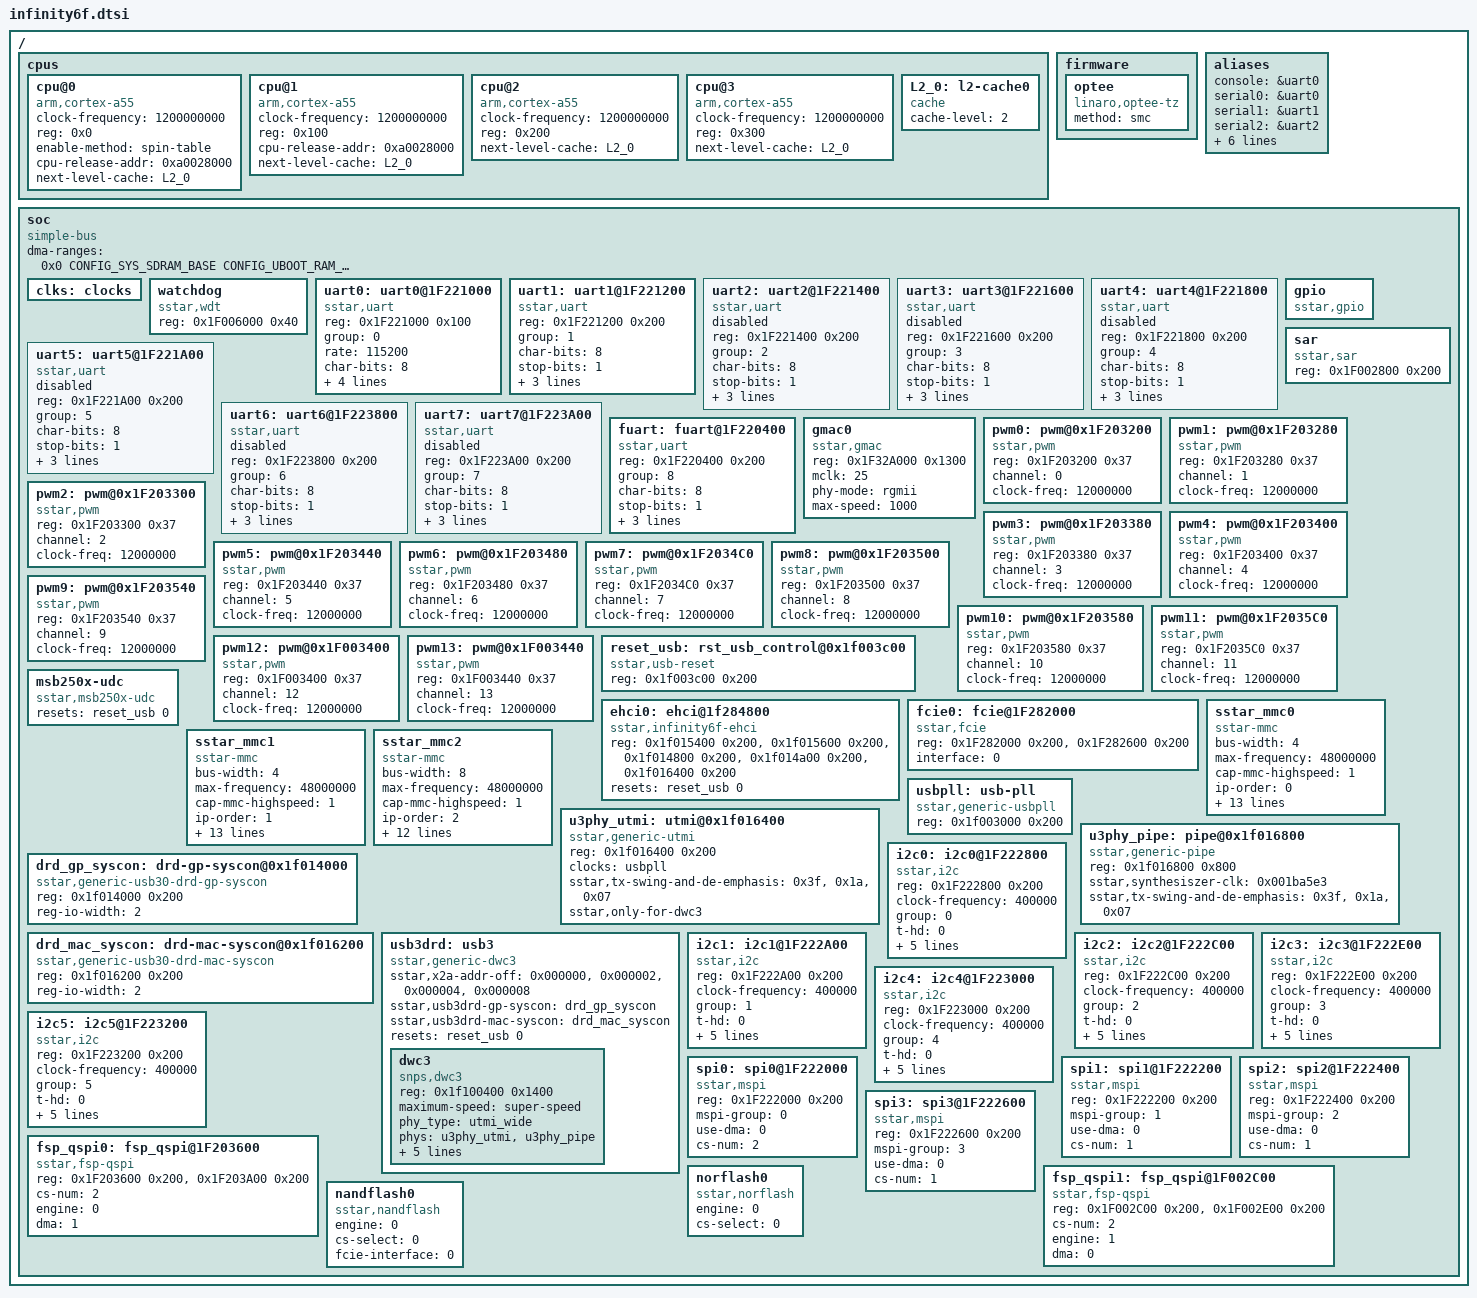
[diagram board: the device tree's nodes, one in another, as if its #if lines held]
/*
* infinity6f.dtsi- Sigmastar
*
* Copyright (c) [2019~2020] SigmaStar Technology.
*
*
* This software is licensed under the terms of the GNU General Public
* License version 2, as published by the Free Software Foundation, and
* may be copied, distributed, and modified under those terms.
*
* This program is distributed in the hope that it will be useful,
* but WITHOUT ANY WARRANTY; without even the implied warranty of
* MERCHANTABILITY or FITNESS FOR A PARTICULAR PURPOSE.  See the
* GNU General Public License version 2 for more details.
*
*/

#include <generated/autoconf.h>
#include "../../../include/configs/infinity6f.h"
#include "../../../drivers/sstar/include/infinity6f/gpio.h"

/*
 * Reserve for TF-A OPTEE and riu recorder
 * 0x24000000 - 0x2403FFFF : TF-A
 * 0x24100000 - 0x241FFFFF : riu recorder
 * 0x24200000 - 0x249FFFFF : OPTEE
 */
/memreserve/ 0x24000000 0x00A00000;

/ {
    cpus {
        #address-cells = <1>;
        #size-cells = <0>;

        cpu@0 {
            device_type = "cpu";
            compatible = "arm,cortex-a55";
            clock-frequency = <1200000000>;
            //clocks = <&CLK_cpupll_clk>;
            reg = <0x0>;
            enable-method = "spin-table";
            cpu-release-addr = <0xa0028000>;
            next-level-cache = <&L2_0>;
        };
#ifndef CONFIG_NO_SMP
        cpu@1 {
            device_type = "cpu";
            compatible = "arm,cortex-a55";
            clock-frequency = <1200000000>;
            reg = <0x100>;
            cpu-release-addr = <0xa0028000>;
            next-level-cache = <&L2_0>;
        };

        cpu@2 {
            device_type = "cpu";
            compatible = "arm,cortex-a55";
            clock-frequency = <1200000000>;
            reg = <0x200>;
            next-level-cache = <&L2_0>;
        };

        cpu@3 {
            device_type = "cpu";
            compatible = "arm,cortex-a55";
            clock-frequency = <1200000000>;
            reg = <0x300>;
            next-level-cache = <&L2_0>;
        };
#endif
        L2_0: l2-cache0 {
            compatible = "cache";
            cache-level = <2>;
        };
    };

#ifdef CONFIG_OPTEE
    firmware {
        optee {
            compatible = "linaro,optee-tz";
            method = "smc";
        };
    };
#endif

    aliases {
        console = &uart0;
        serial0 = &uart0;
        serial1 = &uart1;
        serial2 = &uart2;
        serial3 = &uart3;
        serial4 = &uart4;
        serial5 = &uart5;
        serial6 = &uart6;
        serial7 = &uart7;
        serial8 = &fuart;
    };

    soc {
        compatible = "simple-bus";
        #address-cells = <1>;
        #size-cells = <1>;
        dma-ranges = <0x0 CONFIG_SYS_SDRAM_BASE CONFIG_UBOOT_RAM_SIZE>;
        ranges;

        clks: clocks{
            #address-cells = <1>;
            #size-cells = <1>;
            ranges;
        };

        watchdog: watchdog {
            compatible = "sstar,wdt";
            reg = <0x1F006000 0x40>;
            status = "okay";
        };

        uart0: uart0@1F221000 {
            compatible = "sstar,uart";
            reg = <0x1F221000 0x100>;
            group = <0>;
            rate = <115200>;
            char-bits = <8>;
            stop-bits = <1>;
            parity-en = <0>;
            auto-flow = <0>;
            tolerance = <3>;
            status = "okay";
        };

        uart1: uart1@1F221200 {
            compatible = "sstar,uart";
            reg = <0x1F221200 0x200>;
            group = <1>;
            char-bits = <8>;
            stop-bits = <1>;
            parity-en = <0>; // 0-disable; 1-odd; 2-even.
            auto-flow = <0>;
            tolerance = <3>;
            status = "okay";
        };

        uart2: uart2@1F221400 {
            compatible = "sstar,uart";
            reg = <0x1F221400 0x200>;
            group = <2>;
            char-bits = <8>;
            stop-bits = <1>;
            parity-en = <0>; // 0-disable; 1-odd; 2-even.
            auto-flow = <0>;
            tolerance = <3>;
            status = "disabled";
        };

        uart3: uart3@1F221600 {
            compatible = "sstar,uart";
            reg = <0x1F221600 0x200>;
            group = <3>;
            char-bits = <8>;
            stop-bits = <1>;
            parity-en = <0>; // 0-disable; 1-odd; 2-even.
            auto-flow = <0>;
            tolerance = <3>;
            status = "disabled";
        };

        uart4: uart4@1F221800 {
            compatible = "sstar,uart";
            reg = <0x1F221800 0x200>;
            group = <4>;
            char-bits = <8>;
            stop-bits = <1>;
            parity-en = <0>; // 0-disable; 1-odd; 2-even.
            auto-flow = <0>;
            tolerance = <3>;
            status = "disabled";
        };

        uart5: uart5@1F221A00 {
            compatible = "sstar,uart";
            reg = <0x1F221A00 0x200>;
            group = <5>;
            char-bits = <8>;
            stop-bits = <1>;
            parity-en = <0>; // 0-disable; 1-odd; 2-even.
            auto-flow = <0>;
            tolerance = <3>;
            status = "disabled";
        };

        uart6: uart6@1F223800 {
            compatible = "sstar,uart";
            reg = <0x1F223800 0x200>;
            group = <6>;
            char-bits = <8>;
            stop-bits = <1>;
            parity-en = <0>; // 0-disable; 1-odd; 2-even.
            auto-flow = <0>;
            tolerance = <3>;
            status = "disabled";
        };

        uart7: uart7@1F223A00 {
            compatible = "sstar,uart";
            reg = <0x1F223A00 0x200>;
            group = <7>;
            char-bits = <8>;
            stop-bits = <1>;
            parity-en = <0>; // 0-disable; 1-odd; 2-even.
            auto-flow = <0>;
            tolerance = <3>;
            status = "disabled";
        };

        fuart: fuart@1F220400 {
            compatible = "sstar,uart";
            reg = <0x1F220400 0x200>;
            group = <8>;
            char-bits = <8>;
            stop-bits = <1>;
            parity-en = <0>; // 0-disable; 1-odd; 2-even.
            auto-flow = <0>;
            tolerance = <3>;
            status = "okay";
        };

        gmac0: gmac0 {
            compatible = "sstar,gmac", "snps,dwmac-5.10a";
            reg = <0x1F32A000 0x1300>;
            clock-names = "gmac-clk", "mclk";
            mclk = /bits/ 8 <25>; // Mclk frequency : 0, 25M, 50M
            phy-mode = "rgmii";
            max-speed = <1000>;
            status = "okay";
        };

        gpio: gpio {
            compatible = "sstar,gpio";
            status = "okay";
        };

        sar: sar {
            compatible = "sstar,sar";
            reg = <0x1F002800 0x200>;
            status = "okay";
        };

        pwm0: pwm@0x1F203200{
            compatible = "sstar,pwm";
            reg = <0x1F203200 0x37>;
            channel = <0>;
            clock-freq = <12000000>;
            status = "okay";
        };

        pwm1: pwm@0x1F203280 {
            compatible = "sstar,pwm";
            reg = <0x1F203280 0x37>;
            channel = <1>;
            clock-freq = <12000000>;
            status = "okay";
        };

        pwm2: pwm@0x1F203300 {
            compatible = "sstar,pwm";
            reg = <0x1F203300 0x37>;
            channel = <2>;
            clock-freq = <12000000>;
            status = "okay";
        };

        pwm3: pwm@0x1F203380 {
            compatible = "sstar,pwm";
            reg = <0x1F203380 0x37>;
            channel = <3>;
            clock-freq = <12000000>;
            status = "okay";
        };

        pwm4: pwm@0x1F203400 {
            compatible = "sstar,pwm";
            reg = <0x1F203400 0x37>;
            channel = <4>;
            clock-freq = <12000000>;
            status = "okay";
        };

        pwm5: pwm@0x1F203440 {
            compatible = "sstar,pwm";
            reg = <0x1F203440 0x37>;
            channel = <5>;
            clock-freq = <12000000>;
            status = "okay";
        };

        pwm6: pwm@0x1F203480 {
            compatible = "sstar,pwm";
            reg = <0x1F203480 0x37>;
            channel = <6>;
            clock-freq = <12000000>;
            status = "okay";
        };

        pwm7: pwm@0x1F2034C0 {
            compatible = "sstar,pwm";
            reg = <0x1F2034C0 0x37>;
            channel = <7>;
            clock-freq = <12000000>;
            status = "okay";
        };

        pwm8: pwm@0x1F203500 {
            compatible = "sstar,pwm";
            reg = <0x1F203500 0x37>;
            channel = <8>;
            clock-freq = <12000000>;
            status = "okay";
        };

        pwm9: pwm@0x1F203540 {
            compatible = "sstar,pwm";
            reg = <0x1F203540 0x37>;
            channel = <9>;
            clock-freq = <12000000>;
            status = "okay";
        };

        pwm10: pwm@0x1F203580 {
            compatible = "sstar,pwm";
            reg = <0x1F203580 0x37>;
            channel = <10>;
            clock-freq = <12000000>;
            status = "okay";
        };

        pwm11: pwm@0x1F2035C0 {
            compatible = "sstar,pwm";
            reg = <0x1F2035C0 0x37>;
            channel = <11>;
            clock-freq = <12000000>;
            status = "okay";
        };

        pwm12: pwm@0x1F003400 {
            compatible = "sstar,pwm";
            reg = <0x1F003400 0x37>;
            channel = <12>;
            clock-freq = <12000000>;
            status = "okay";
        };

        pwm13: pwm@0x1F003440 {
            compatible = "sstar,pwm";
            reg = <0x1F003440 0x37>;
            channel = <13>;
            clock-freq = <12000000>;
            status = "okay";
        };

        reset_usb: rst_usb_control@0x1f003c00 {
            compatible = "sstar,usb-reset";
            reg = <0x1f003c00 0x200>;
            #reset-cells = <1>;
            status = "okay";
        };

        msb250x-udc {
            compatible = "sstar,msb250x-udc";
            resets = <&reset_usb 0>;
            status = "okay";
        };

        ehci0: ehci@1f284800{
            compatible = "sstar,infinity6f-ehci";
            reg = <0x1f015400 0x200>,
                  <0x1f015600 0x200>,
                  <0x1f014800 0x200>,
                  <0x1f014a00 0x200>,
                  <0x1f016400 0x200>;
            resets = <&reset_usb 0>;
            status = "okay";
        };

        fcie0: fcie@1F282000 {
            compatible = "sstar,fcie";
            reg = <0x1F282000 0x200>, <0x1F282600 0x200>;
            interface = <0>;
            status = "okay";
        };

        sstar_mmc0: sstar_mmc0 {
            compatible = "sstar-mmc";

            bus-width = <4>;
            max-frequency = <48000000>;
            cap-mmc-highspeed = <1>;
            ip-order = <0>;
            pad-order = <0>;
            pwr-on-delay = <10>;
            pwr-off-delay = <50>;
            fake-cdz = <0>;
            rev-cdz = <0>;
            pwr-pad = <PAD_SD0_GPIO0>;
            cdz-pad = <PAD_SD0_CDZ>;
            clk-driving = <1>;
            cmd-driving = <1>;
            data-driving = <1>;
            en-clk-phase = <0>;
            rx-clk-phase = <0>;
            tx-clk-phase = <0>;
            status = "okay";
        };

        sstar_mmc1: sstar_mmc1 {
            compatible = "sstar-mmc";

            bus-width = <4>;
            max-frequency = <48000000>;
            cap-mmc-highspeed = <1>;
            ip-order = <1>;
            pad-order = <0>;
            pwr-on-delay = <10>;
            pwr-off-delay = <50>;
            fake-cdz = <0>;
            rev-cdz = <0>;
            pwr-pad = <PAD_SD1_GPIO0>;
            cdz-pad = <PAD_SD1_CDZ>;
            clk-driving = <1>;
            cmd-driving = <1>;
            data-driving = <1>;
            en-clk-phase = <0>;
            rx-clk-phase = <0>;
            tx-clk-phase = <0>;
            status = "okay";
        };

        sstar_mmc2: sstar_mmc2 {
            compatible = "sstar-mmc";

            bus-width = <8>;
            max-frequency = <48000000>;
            cap-mmc-highspeed = <1>;
            ip-order = <2>;
            pad-order = <0>;
            pwr-on-delay = <10>;
            pwr-off-delay = <50>;
            fake-cdz = <0>;
            rev-cdz = <0>;
            clk-driving = <1>;
            cmd-driving = <1>;
            data-driving = <1>;
            en-clk-phase = <0>;
            rx-clk-phase = <0>;
            tx-clk-phase = <0>;

            non-removable = <1>;
            status = "okay";
        };

        usbpll: usb-pll {
            compatible = "sstar,generic-usbpll";
            reg = <0x1f003000 0x200>;
            #clock-cells = <0>;
            status = "okay";
        };

        u3phy_utmi: utmi@0x1f016400 {
            compatible = "sstar,generic-utmi";
            reg = <0x1f016400 0x200>;
            clocks = <&usbpll>;
            sstar,tx-swing-and-de-emphasis = <0x3f>, <0x1a>, <0x07>;
            sstar,only-for-dwc3;
            #phy-cells = <0>;
            status = "okay";
        };

        u3phy_pipe: pipe@0x1f016800 {
            compatible = "sstar,generic-pipe";
            reg = <0x1f016800 0x800>;
            //clocks = <&CLK_ssusb_phy_108>, <&CLK_ssusb_phy_432>;
            sstar,synthesiszer-clk = <0x001ba5e3>;
            sstar,tx-swing-and-de-emphasis = <0x3f>, <0x1a>, <0x07>;
            #phy-cells = <0>;
            status = "okay";
       };

        drd_gp_syscon: drd-gp-syscon@0x1f014000 {
            compatible = "sstar,generic-usb30-drd-gp-syscon", "syscon";
            reg = <0x1f014000 0x200>;
            reg-io-width = <2>;
            status = "okay";
        };

        drd_mac_syscon: drd-mac-syscon@0x1f016200 {
            compatible = "sstar,generic-usb30-drd-mac-syscon", "syscon";
            reg = <0x1f016200 0x200>;
            reg-io-width = <2>;
            status = "okay";
        };

        usb3drd: usb3 {
            compatible = "sstar,generic-dwc3";
            //clocks = <&CLK_sof_usb30_drd>;
            sstar,x2a-addr-off = <0x000000>, <0x000002>, <0x000004>, <0x000008>;
            sstar,usb3drd-gp-syscon = <&drd_gp_syscon>;
            sstar,usb3drd-mac-syscon = <&drd_mac_syscon>;
            resets = <&reset_usb 0>;
            #address-cells = <1>;
            #size-cells = <1>;
            ranges;
            status = "okay";

            dwc3: dwc3 {
                compatible = "snps,dwc3";
                reg = <0x1f100400 0x1400>;
                maximum-speed = "super-speed";
                phy_type = "utmi_wide";
                phys = <&u3phy_utmi>, <&u3phy_pipe>;
                phy-names = "usb2-phy", "usb3-phy";
                snps,incr-burst-type-adjustment = <1>, <4>, <8>, <16>;
                snps,dis_u3_susphy_quirk;
                snps,dis_u2_susphy_quirk;
                snps,usb3_lpm_capable;
                linux,sysdev_is_parent;
                status = "okay";
            };
        };

        i2c0: i2c0@1F222800 {
            compatible = "sstar,i2c";
            reg = <0x1F222800 0x200>;
            clock-frequency = <400000>;
            group = <0>;
            t-hd = <0>;//if u want set tHD,set here not 0,tHD = (t-hd / i2c-srcclk)S
            t-su = <0>;//if u want set tSU,set here not 0,tSU = (t-su / i2c-srcclk)S
            t-start = <0>;
            t-stop = <0>;
            push-pull = <1>;//set 1 enable push-pull output,set 0 open drain
            oen-cnt   = <0>;
            status = "okay";
        };

        i2c1: i2c1@1F222A00 {
            compatible = "sstar,i2c";
            reg = <0x1F222A00 0x200>;
            clock-frequency = <400000>;
            group = <1>;
            t-hd = <0>;
            t-su = <0>;
            t-start = <0>;
            t-stop = <0>;
            push-pull = <1>;
            oen-cnt   = <0>;
            status = "okay";
        };

        i2c2: i2c2@1F222C00 {
            compatible = "sstar,i2c";
            reg = <0x1F222C00 0x200>;
            clock-frequency = <400000>;
            group = <2>;
            t-hd = <0>;
            t-su = <0>;
            t-start = <0>;
            t-stop = <0>;
            push-pull = <1>;
            oen-cnt   = <0>;
            status = "okay";
        };

        i2c3: i2c3@1F222E00 {
            compatible = "sstar,i2c";
            reg = <0x1F222E00 0x200>;
            clock-frequency = <400000>;
            group = <3>;
            t-hd = <0>;
            t-su = <0>;
            t-start = <0>;
            t-stop = <0>;
            push-pull = <1>;
            oen-cnt   = <0>;
            status = "okay";
        };

        i2c4: i2c4@1F223000 {
            compatible = "sstar,i2c";
            reg = <0x1F223000 0x200>;
            clock-frequency = <400000>;
            group = <4>;
            t-hd = <0>;
            t-su = <0>;
            t-start = <0>;
            t-stop = <0>;
            push-pull = <1>;
            oen-cnt   = <0>;
            status = "okay";
        };

        i2c5: i2c5@1F223200 {
            compatible = "sstar,i2c";
            reg = <0x1F223200 0x200>;
            clock-frequency = <400000>;
            group = <5>;
            t-hd = <0>;
            t-su = <0>;
            t-start = <0>;
            t-stop = <0>;
            push-pull = <1>;
            oen-cnt   = <0>;
            status = "okay";
        };

        spi0: spi0@1F222000 {
            compatible = "sstar,mspi";
            reg = <0x1F222000 0x200>;
            mspi-group = <0>;
            use-dma = <0>;
            cs-num = <2>;
            //cs-ext = <PAD_UNKNOWN>;
            //4to3-mode;
            //clk-out-mode = <27000000>;
            status = "okay";
        };

        spi1: spi1@1F222200 {
            compatible = "sstar,mspi";
            reg = <0x1F222200 0x200>;
            mspi-group = <1>;
            use-dma = <0>;
            cs-num = <1>;
            //cs-ext = <PAD_UNKNOWN>;
            //4to3-mode;
            //clk-out-mode = <27000000>;
            status = "okay";
        };

        spi2: spi2@1F222400 {
            compatible = "sstar,mspi";
            reg = <0x1F222400 0x200>;
            mspi-group = <2>;
            use-dma = <0>;
            cs-num = <1>;
            //cs-ext = <PAD_UNKNOWN>;
            //4to3-mode;
            //clk-out-mode = <27000000>;
            status = "okay";
        };

        spi3: spi3@1F222600 {
            compatible = "sstar,mspi";
            reg = <0x1F222600 0x200>;
            mspi-group = <3>;
            use-dma = <0>;
            cs-num = <1>;
            //cs-ext = <PAD_UNKNOWN>;
            //4to3-mode;
            //clk-out-mode = <27000000>;
            status = "okay";
        };

        fsp_qspi0: fsp_qspi@1F203600 {
            compatible = "sstar,fsp-qspi";
            reg = <0x1F203600 0x200>, <0x1F203A00 0x200>;
            cs-num = <2>;
            engine = <0>;
            dma = <1>;
            status = "okay";
        };

        fsp_qspi1: fsp_qspi@1F002C00 {
            compatible = "sstar,fsp-qspi";
            reg = <0x1F002C00 0x200>, <0x1F002E00 0x200>;
            cs-num = <2>;
            engine = <1>;
            dma = <0>;
            status = "okay";
        };

        norflash0 {
            compatible = "sstar,norflash";
            engine = <0>;
            cs-select = <0>;
            status = "okay";
        };

        nandflash0 {
            compatible = "sstar,nandflash";
            engine = <0>;
            cs-select = <0>;
            fcie-interface = <0>;
            status = "okay";
        };
    };
};

&clks {
    #address-cells = <1>;
    #size-cells = <1>;
};
